# ddr32ss_EMIF_CTLCFG_0F308000h register map
Vendor: Texas Instruments
Registers are 32-bit, read-write, reset 0x0 unless marked. A register's access mark holds for its fields unless they carry their own. Offsets are as the file gives them; [hi:lo] are bit positions; {n}, {i} and the like mark numbered series.

## emif_ctlcfg (part 5 of 13)
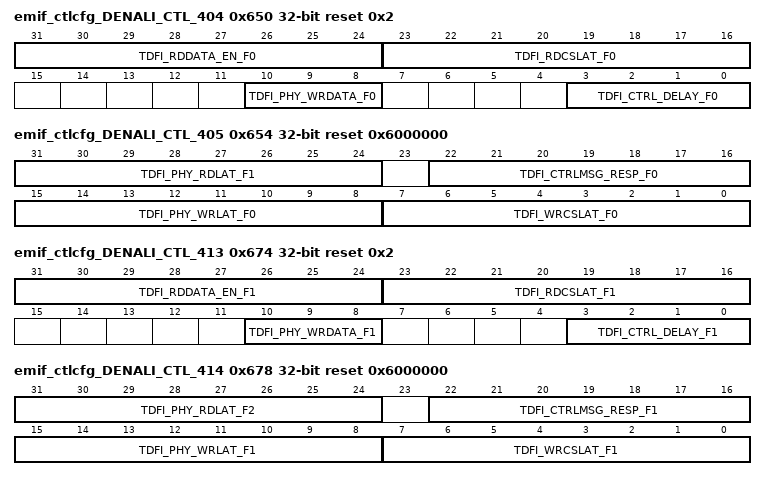
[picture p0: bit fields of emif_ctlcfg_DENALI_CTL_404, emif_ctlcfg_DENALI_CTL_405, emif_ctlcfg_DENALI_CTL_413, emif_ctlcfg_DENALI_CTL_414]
0x650 emif_ctlcfg_DENALI_CTL_404 reset 0x2
  [31:24] TDFI_RDDATA_EN_F0 — DFI tRDDATA_EN timing parameter. This is the number of DFI data phases between a read command and the first assertion of dfi_rddata_en_pN. FC=0 Reset Source: ctl_amod_g_rst_n
  [23:16] TDFI_RDCSLAT_F0 — Defines the DFI tPHY_RDCSLAT timing parameter [in DFI PHY clocks], the maximum cycles between a read command and a dfi_rddata_cs_n assertion. FC=0 Reset Source: ctl_amod_g_rst_n
  [10:8] TDFI_PHY_WRDATA_F0 — Defines the DFI tPHY_WRDATA timing parameter [in DFI PHY clocks], the maximum cycles between a dfi_wrdata_en assertion and a dfi_wrdata signal. FC=0 Reset Source: ctl_amod_g_rst_n
  [3:0] TDFI_CTRL_DELAY_F0 — Defines the DFI tCTRL_DELAY timing parameter [in DFI clocks], the delay between a DFI command change and a memory command. FC=0 Reset Source: ctl_amod_g_rst_n
0x654 emif_ctlcfg_DENALI_CTL_405 reset 0x6000000
  [31:24] TDFI_PHY_RDLAT_F1 — Defines the DFI tPHY_RDLAT timing parameter [in DFI PHY clocks], the maximum cycles between a dfi_rddata_en assertion and a dfi_rddata_valid assertion. FC=1 Reset Source: ctl_amod_g_rst_n
  [22:16] TDFI_CTRLMSG_RESP_F0 — Defines the DFI tCTRLMSG_RESP timing parameter [in DFI clocks], the maximum number of DFI clocks allowed for dfi_ctrlmsg_ack to assert after dfi_ctrlmsg_req goes high. FC=0 Reset Source: ctl_amod_g_rst_n
  [15:8] TDFI_PHY_WRLAT_F0 — DFI tPHY_WRLAT timing parameter. This is the number of DFI data phases between a write command and the first assertion of dfi_wrdata_en_pN. FC=0 Reset Source: ctl_amod_g_rst_n
  [7:0] TDFI_WRCSLAT_F0 — Defines the DFI tPHY_WRCSLAT timing parameter [in DFI PHY clocks], the maximum cycles between a write command and a dfi_wrdata_cs_n assertion. FC=0 Reset Source: ctl_amod_g_rst_n
0x658 emif_ctlcfg_DENALI_CTL_406
  [20:0] TDFI_CTRLUPD_MAX_F1 — Defines the DFI tCTRLUPD_MAX timing parameter [in DFI clocks], the maximum cycles that dfi_ctrlupd_req can be asserted. If programmed to a non-zero, a timing violation will cause an interrupt and bit [0] set in the UPDATE_ERROR_STATUS parameter. FC=1 Reset Source: ctl_amod_g_rst_n
{0x0+4i} emif_ctlcfg_DENALI_CTL_{i} (i=407..410)
  [31:0] TDFI_PHYUPD_TYPE{i-407}_F1 — Defines the DFI tPHYUPD_TYPE{i-407} timing parameter [in DFI clocks], the maximum cycles that dfi_phyupd_req can assert after dfi_phyupd_ack for dfi_phyupd_type {i-407}. If programmed to a non-zero, a timing violation will cause an interrupt and bit [{i-406}] set in the UPDATE_ERROR_STATUS parameter. FC=1 Reset Source: ctl_amod_g_rst_n
0x66C emif_ctlcfg_DENALI_CTL_411
  [22:0] TDFI_PHYUPD_RESP_F1 — Defines the DFI tPHYUPD_RESP timing parameter [in DFI clocks], the maximum cycles between a dfi_phyupd_req assertion and a dfi_phyupd_ack assertion. If programmed to a non-zero, a timing violation will cause an interrupt and bit [5] set in the UPDATE_ERROR_STATUS parameter. FC=1 Reset Source: ctl_amod_g_rst_n
0x670 emif_ctlcfg_DENALI_CTL_412
  [31:0] TDFI_CTRLUPD_INTERVAL_F1 — Defines the DFI tCTRLUPD_INTERVAL timing parameter [in DFI clocks], the maximum cycles between dfi_ctrlupd_req assertions. If programmed to a non-zero, a timing violation will cause an interrupt and bit [6] set in the UPDATE_ERROR_STATUS parameter. FC=1 Reset Source: ctl_amod_g_rst_n
0x674 emif_ctlcfg_DENALI_CTL_413 reset 0x2
  [31:24] TDFI_RDDATA_EN_F1 — DFI tRDDATA_EN timing parameter. This is the number of DFI data phases between a read command and the first assertion of dfi_rddata_en_pN. FC=1 Reset Source: ctl_amod_g_rst_n
  [23:16] TDFI_RDCSLAT_F1 — Defines the DFI tPHY_RDCSLAT timing parameter [in DFI PHY clocks], the maximum cycles between a read command and a dfi_rddata_cs_n assertion. FC=1 Reset Source: ctl_amod_g_rst_n
  [10:8] TDFI_PHY_WRDATA_F1 — Defines the DFI tPHY_WRDATA timing parameter [in DFI PHY clocks], the maximum cycles between a dfi_wrdata_en assertion and a dfi_wrdata signal. FC=1 Reset Source: ctl_amod_g_rst_n
  [3:0] TDFI_CTRL_DELAY_F1 — Defines the DFI tCTRL_DELAY timing parameter [in DFI clocks], the delay between a DFI command change and a memory command. FC=1 Reset Source: ctl_amod_g_rst_n
0x678 emif_ctlcfg_DENALI_CTL_414 reset 0x6000000
  [31:24] TDFI_PHY_RDLAT_F2 — Defines the DFI tPHY_RDLAT timing parameter [in DFI PHY clocks], the maximum cycles between a dfi_rddata_en assertion and a dfi_rddata_valid assertion. FC=2 Reset Source: ctl_amod_g_rst_n
  [22:16] TDFI_CTRLMSG_RESP_F1 — Defines the DFI tCTRLMSG_RESP timing parameter [in DFI clocks], the maximum number of DFI clocks allowed for dfi_ctrlmsg_ack to assert after dfi_ctrlmsg_req goes high. FC=1 Reset Source: ctl_amod_g_rst_n
  [15:8] TDFI_PHY_WRLAT_F1 — DFI tPHY_WRLAT timing parameter. This is the number of DFI data phases between a write command and the first assertion of dfi_wrdata_en_pN. FC=1 Reset Source: ctl_amod_g_rst_n
  [7:0] TDFI_WRCSLAT_F1 — Defines the DFI tPHY_WRCSLAT timing parameter [in DFI PHY clocks], the maximum cycles between a write command and a dfi_wrdata_cs_n assertion. FC=1 Reset Source: ctl_amod_g_rst_n
0x67C emif_ctlcfg_DENALI_CTL_415
  [20:0] TDFI_CTRLUPD_MAX_F2 — Defines the DFI tCTRLUPD_MAX timing parameter [in DFI clocks], the maximum cycles that dfi_ctrlupd_req can be asserted. If programmed to a non-zero, a timing violation will cause an interrupt and bit [0] set in the UPDATE_ERROR_STATUS parameter. FC=2 Reset Source: ctl_amod_g_rst_n
{0x0+4i} emif_ctlcfg_DENALI_CTL_{i} (i=416..419)
  [31:0] TDFI_PHYUPD_TYPE{i-416}_F2 — Defines the DFI tPHYUPD_TYPE{i-416} timing parameter [in DFI clocks], the maximum cycles that dfi_phyupd_req can assert after dfi_phyupd_ack for dfi_phyupd_type {i-416}. If programmed to a non-zero, a timing violation will cause an interrupt and bit [{i-415}] set in the UPDATE_ERROR_STATUS parameter. FC=2 Reset Source: ctl_amod_g_rst_n
0x690 emif_ctlcfg_DENALI_CTL_420
  [22:0] TDFI_PHYUPD_RESP_F2 — Defines the DFI tPHYUPD_RESP timing parameter [in DFI clocks], the maximum cycles between a dfi_phyupd_req assertion and a dfi_phyupd_ack assertion. If programmed to a non-zero, a timing violation will cause an interrupt and bit [5] set in the UPDATE_ERROR_STATUS parameter. FC=2 Reset Source: ctl_amod_g_rst_n
0x694 emif_ctlcfg_DENALI_CTL_421
  [31:0] TDFI_CTRLUPD_INTERVAL_F2 — Defines the DFI tCTRLUPD_INTERVAL timing parameter [in DFI clocks], the maximum cycles between dfi_ctrlupd_req assertions. If programmed to a non-zero, a timing violation will cause an interrupt and bit [6] set in the UPDATE_ERROR_STATUS parameter. FC=2 Reset Source: ctl_amod_g_rst_n
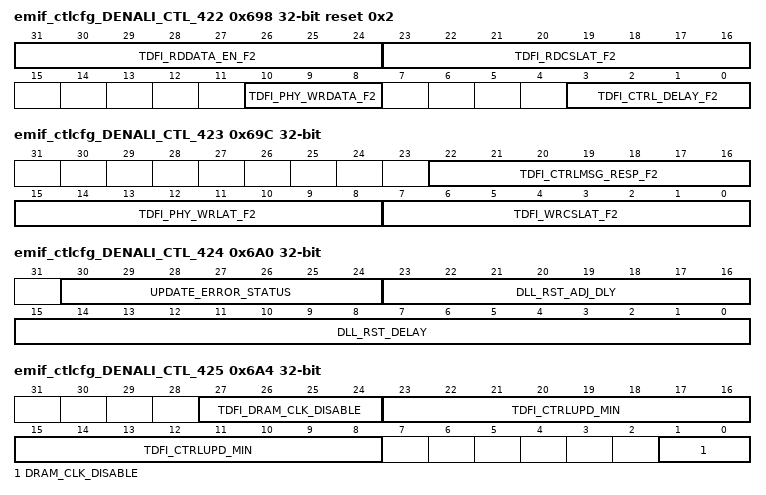
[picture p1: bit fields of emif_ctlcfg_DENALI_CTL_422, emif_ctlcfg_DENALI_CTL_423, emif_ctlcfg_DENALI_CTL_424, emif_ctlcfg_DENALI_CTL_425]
0x698 emif_ctlcfg_DENALI_CTL_422 reset 0x2
  [31:24] TDFI_RDDATA_EN_F2 — DFI tRDDATA_EN timing parameter. This is the number of DFI data phases between a read command and the first assertion of dfi_rddata_en_pN. FC=2 Reset Source: ctl_amod_g_rst_n
  [23:16] TDFI_RDCSLAT_F2 — Defines the DFI tPHY_RDCSLAT timing parameter [in DFI PHY clocks], the maximum cycles between a read command and a dfi_rddata_cs_n assertion. FC=2 Reset Source: ctl_amod_g_rst_n
  [10:8] TDFI_PHY_WRDATA_F2 — Defines the DFI tPHY_WRDATA timing parameter [in DFI PHY clocks], the maximum cycles between a dfi_wrdata_en assertion and a dfi_wrdata signal. FC=2 Reset Source: ctl_amod_g_rst_n
  [3:0] TDFI_CTRL_DELAY_F2 — Defines the DFI tCTRL_DELAY timing parameter [in DFI clocks], the delay between a DFI command change and a memory command. FC=2 Reset Source: ctl_amod_g_rst_n
0x69C emif_ctlcfg_DENALI_CTL_423
  [22:16] TDFI_CTRLMSG_RESP_F2 — Defines the DFI tCTRLMSG_RESP timing parameter [in DFI clocks], the maximum number of DFI clocks allowed for dfi_ctrlmsg_ack to assert after dfi_ctrlmsg_req goes high. FC=2 Reset Source: ctl_amod_g_rst_n
  [15:8] TDFI_PHY_WRLAT_F2 — DFI tPHY_WRLAT timing parameter. This is the number of DFI data phases between a write command and the first assertion of dfi_wrdata_en_pN. FC=2 Reset Source: ctl_amod_g_rst_n
  [7:0] TDFI_WRCSLAT_F2 — Defines the DFI tPHY_WRCSLAT timing parameter [in DFI PHY clocks], the maximum cycles between a write command and a dfi_wrdata_cs_n assertion. FC=2 Reset Source: ctl_amod_g_rst_n
0x6A0 emif_ctlcfg_DENALI_CTL_424 access per field
  [30:24] UPDATE_ERROR_STATUS ro — Identifies the source of any DFI MC-initiated or PHY-initiated update errors. Value of 1 indicates a timing violation of the associated timing parameter. READ-ONLY Reset Source: ctl_amod_g_rst_n
  [23:16] DLL_RST_ADJ_DLY rw — Minimum cycles after setting master delay in DLL until the DLL reset signal dll_rst_n may be asserted. If this signal is not being used by the PHY, this parameter may be ignored. Reset Source: ctl_amod_g_rst_n
  [15:0] DLL_RST_DELAY rw — Minimum cycles required for DLL reset signal dll_rst_n to be held. If this signal is not being used by the PHY, this parameter may be ignored. Reset Source: ctl_amod_g_rst_n
0x6A4 emif_ctlcfg_DENALI_CTL_425
  [27:24] TDFI_DRAM_CLK_DISABLE — Defines the DFI tDRAM_CLK_DISABLE timing parameter [in DFI clocks], the delay between a dfi_dram_clock_disable assertion and the memory clock disable. Reset Source: ctl_amod_g_rst_n
  [23:8] TDFI_CTRLUPD_MIN — Defines the DFI tCTRLUPD_MIN timing parameter [in DFI clocks], the minimum cycles that dfi_ctrlupd_req must be asserted. Reset Source: ctl_amod_g_rst_n
  [1:0] DRAM_CLK_DISABLE — Set value for the dfi_dram_clk_disable signal. Bit [0] controls cs0, bit [1] controls cs1, etc. Set each bit to 1 to disable. Reset Source: ctl_amod_g_rst_n
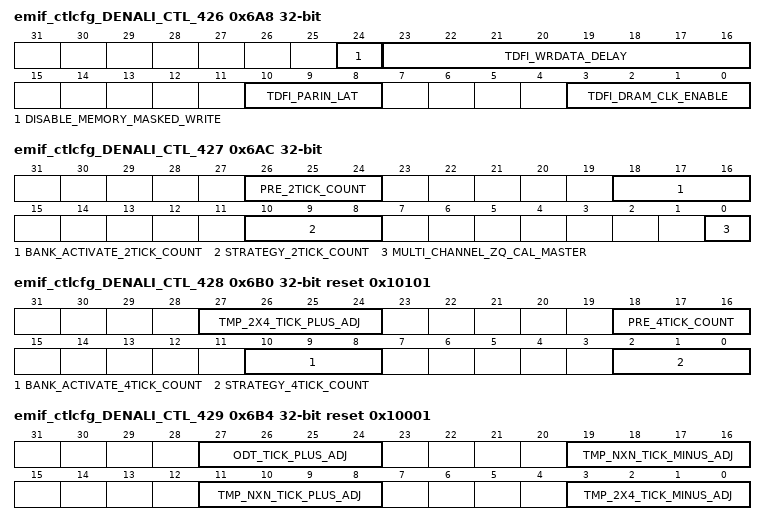
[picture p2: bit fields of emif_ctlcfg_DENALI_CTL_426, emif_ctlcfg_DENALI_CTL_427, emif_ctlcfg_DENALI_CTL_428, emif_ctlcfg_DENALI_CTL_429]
0x6A8 emif_ctlcfg_DENALI_CTL_426
  [24] DISABLE_MEMORY_MASKED_WRITE — Restricts the controller from masked write commands. Set to 1 to not issue these commands. Only used if connected to an LPDDR4 device. Reset Source: ctl_amod_g_rst_n
  [23:16] TDFI_WRDATA_DELAY — Defines the tWRDATA_DELAY timing parameter [in DFI PHY clocks], the maximum cycles between when the dfi_wrdata_en signal is asserted and when the corresponding write data transfer is completed on the DRAM bus. Reset Source: ctl_amod_g_rst_n
  [10:8] TDFI_PARIN_LAT — Defines the DFI tPARIN_LAT timing parameter [in DFI PHY clocks], the maximum cycles between a DFI command and a dfi_parity_in signal assertion. Reset Source: ctl_amod_g_rst_n
  [3:0] TDFI_DRAM_CLK_ENABLE — Defines the DFI tDRAM_CLK_ENABLE timing parameter [in DFI clocks], the delay between a dfi_dram_clk_disable de-assertion and the memory clock enable. Reset Source: ctl_amod_g_rst_n
0x6AC emif_ctlcfg_DENALI_CTL_427
  [26:24] PRE_2TICK_COUNT — NEED TO FiLL IN . Reset Source: ctl_amod_g_rst_n
  [18:16] BANK_ACTIVATE_2TICK_COUNT — NEED TO FiLL IN . Reset Source: ctl_amod_g_rst_n
  [10:8] STRATEGY_2TICK_COUNT — NEED TO FiLL IN . Reset Source: ctl_amod_g_rst_n
  [0] MULTI_CHANNEL_ZQ_CAL_MASTER — In a two controller scenario, defines if this controller will issue ZQ calibration start commands when neither controller is in a low power mode. Set to 1 to define this controller as the master that issues ZQ calibration start commands or clear to 0 to define this controller as the target. This parameter should only be programmed once during initialization. Reset Source: ctl_amod_g_rst_n
0x6B0 emif_ctlcfg_DENALI_CTL_428 reset 0x10101
  [27:24] TMP_2X4_TICK_PLUS_ADJ — NEED TO FiLL IN . Reset Source: ctl_amod_g_rst_n
  [18:16] PRE_4TICK_COUNT — NEED TO FiLL IN . Reset Source: ctl_amod_g_rst_n
  [10:8] BANK_ACTIVATE_4TICK_COUNT — NEED TO FiLL IN . Reset Source: ctl_amod_g_rst_n
  [2:0] STRATEGY_4TICK_COUNT — NEED TO FiLL IN . Reset Source: ctl_amod_g_rst_n
0x6B4 emif_ctlcfg_DENALI_CTL_429 reset 0x10001
  [27:24] ODT_TICK_PLUS_ADJ — NEED TO FiLL IN . Reset Source: ctl_amod_g_rst_n
  [19:16] TMP_NXN_TICK_MINUS_ADJ — NEED TO FiLL IN . Reset Source: ctl_amod_g_rst_n
  [11:8] TMP_NXN_TICK_PLUS_ADJ — NEED TO FiLL IN . Reset Source: ctl_amod_g_rst_n
  [3:0] TMP_2X4_TICK_MINUS_ADJ — NEED TO FiLL IN . Reset Source: ctl_amod_g_rst_n
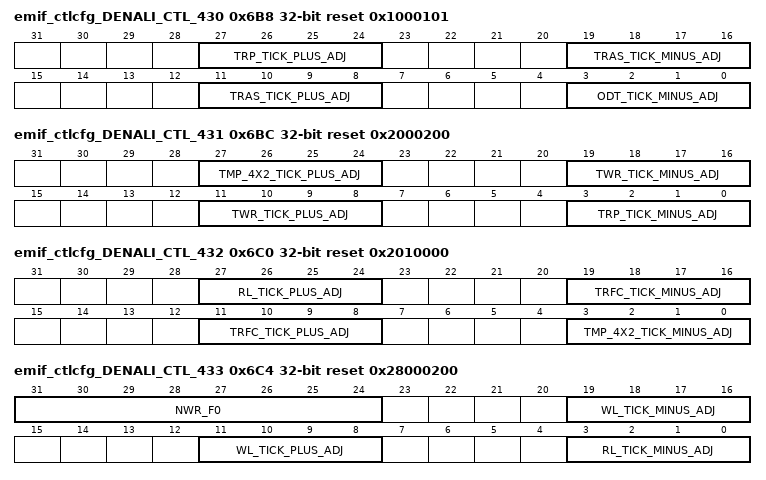
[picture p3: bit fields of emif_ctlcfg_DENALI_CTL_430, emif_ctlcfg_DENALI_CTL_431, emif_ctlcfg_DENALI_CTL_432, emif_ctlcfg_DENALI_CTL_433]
0x6B8 emif_ctlcfg_DENALI_CTL_430 reset 0x1000101
  [27:24] TRP_TICK_PLUS_ADJ — NEED TO FiLL IN . Reset Source: ctl_amod_g_rst_n
  [19:16] TRAS_TICK_MINUS_ADJ — NEED TO FiLL IN . Reset Source: ctl_amod_g_rst_n
  [11:8] TRAS_TICK_PLUS_ADJ — NEED TO FiLL IN . Reset Source: ctl_amod_g_rst_n
  [3:0] ODT_TICK_MINUS_ADJ — NEED TO FiLL IN . Reset Source: ctl_amod_g_rst_n
0x6BC emif_ctlcfg_DENALI_CTL_431 reset 0x2000200
  [27:24] TMP_4X2_TICK_PLUS_ADJ — NEED TO FiLL IN . Reset Source: ctl_amod_g_rst_n
  [19:16] TWR_TICK_MINUS_ADJ — NEED TO FiLL IN . Reset Source: ctl_amod_g_rst_n
  [11:8] TWR_TICK_PLUS_ADJ — NEED TO FiLL IN . Reset Source: ctl_amod_g_rst_n
  [3:0] TRP_TICK_MINUS_ADJ — NEED TO FiLL IN . Reset Source: ctl_amod_g_rst_n
0x6C0 emif_ctlcfg_DENALI_CTL_432 reset 0x2010000
  [27:24] RL_TICK_PLUS_ADJ — NEED TO FiLL IN . Reset Source: ctl_amod_g_rst_n
  [19:16] TRFC_TICK_MINUS_ADJ — NEED TO FiLL IN . Reset Source: ctl_amod_g_rst_n
  [11:8] TRFC_TICK_PLUS_ADJ — NEED TO FiLL IN . Reset Source: ctl_amod_g_rst_n
  [3:0] TMP_4X2_TICK_MINUS_ADJ — NEED TO FiLL IN . Reset Source: ctl_amod_g_rst_n
0x6C4 emif_ctlcfg_DENALI_CTL_433 reset 0x28000200
  [31:24] NWR_F0 — DRAM NWR value in cycles. FC=0 Reset Source: ctl_amod_g_rst_n
  [19:16] WL_TICK_MINUS_ADJ — NEED TO FiLL IN . Reset Source: ctl_amod_g_rst_n
  [11:8] WL_TICK_PLUS_ADJ — NEED TO FiLL IN . Reset Source: ctl_amod_g_rst_n
  [3:0] RL_TICK_MINUS_ADJ — NEED TO FiLL IN . Reset Source: ctl_amod_g_rst_n
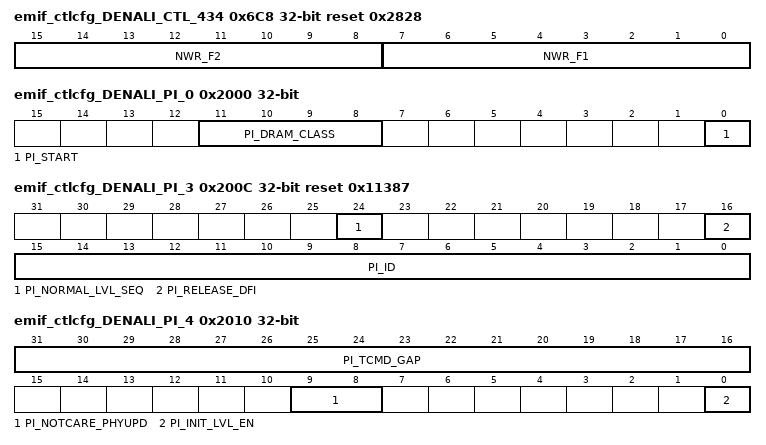
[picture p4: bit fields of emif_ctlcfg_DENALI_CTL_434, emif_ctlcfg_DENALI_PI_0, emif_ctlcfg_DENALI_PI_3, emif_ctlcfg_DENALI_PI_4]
0x6C8 emif_ctlcfg_DENALI_CTL_434 reset 0x2828
  [15:8] NWR_F2 — DRAM NWR value in cycles. FC=2 Reset Source: ctl_amod_g_rst_n
  [7:0] NWR_F1 — DRAM NWR value in cycles. FC=1 Reset Source: ctl_amod_g_rst_n
0x2000 emif_ctlcfg_DENALI_PI_0
  [11:8] PI_DRAM_CLASS — Defines the memory class for the PI. Reset Source: ctl_amod_g_rst_n
  [0] PI_START — Initiate command processing in the PI. Set to 1 to initiate. Reset Source: ctl_amod_g_rst_n
0x2004 emif_ctlcfg_DENALI_PI_1 ro reset 0x30BD08BA
  [31:0] PI_VERSION_0 — Holds the PI version number. This is a unique number for each PHY IP delivery. This will help in identifying different version of the PHY IP. READ-ONLY Reset Source: ctl_amod_g_rst_n
0x2008 emif_ctlcfg_DENALI_PI_2 ro reset 0x453CB5C
  [31:0] PI_VERSION_1 — Holds the PI version number. This is a unique number for each PHY IP delivery. This will help in identifying different version of the PHY IP. READ-ONLY Reset Source: ctl_amod_g_rst_n
0x200C emif_ctlcfg_DENALI_PI_3 access per field reset 0x11387
  [24] PI_NORMAL_LVL_SEQ rw — Enable the PI to finish all the pending leveling before releasing the DFI bus. Reset Source: ctl_amod_g_rst_n
  [16] PI_RELEASE_DFI ro — This is a status whether PI has release DFI. READ-ONLY. Reset Source: ctl_amod_g_rst_n
  [15:0] PI_ID ro — Holds the PI ID number. This is a Cadence DDR PHY IP identifier. It is set to 0x1387. READ-ONLY Reset Source: ctl_amod_g_rst_n
0x2010 emif_ctlcfg_DENALI_PI_4
  [31:16] PI_TCMD_GAP — Specifies the minimum gap in DFI clocks between two commands. Used to guard the timing from the last command of MC and the first command of PI when MC hand over the control of DFI to PI. Reset Source: ctl_amod_g_rst_n
  [9:8] PI_NOTCARE_PHYUPD — Allow the PI to issue a master request to the controller if a phyupd_req from the PHY has been detected.bit[1] represents supports in normal state;bit[0] represents supports in initialization state. Set to 1 to issue the master request. Reset Source: ctl_amod_g_rst_n
  [0] PI_INIT_LVL_EN — Enables the initial leveling sequence after PI initialization procedure. Set to 1 to enable. Reset Source: ctl_amod_g_rst_n
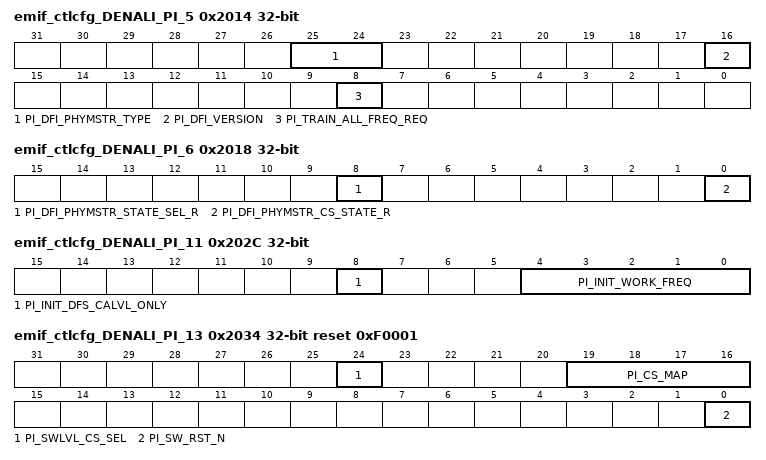
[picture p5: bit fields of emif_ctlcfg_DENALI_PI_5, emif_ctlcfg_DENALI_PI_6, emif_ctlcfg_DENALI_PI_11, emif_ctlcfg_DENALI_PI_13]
0x2014 emif_ctlcfg_DENALI_PI_5 access per field
  [25:24] PI_DFI_PHYMSTR_TYPE rw — DFI Master Request Type used for dfi 4.1 verision: This signal indicates the required state of DRAM when PHY becomes the master. Each memory rank uses one bit. 1'b0: IDLE. The MC should close all the pages. 1'b1: IDLE or Self Refresh. Reset Source: ctl_amod_g_rst_n
  [16] PI_DFI_VERSION rw — Define the DFI master version, set 1 for DFI4.1, set 0 for DFI4.0 Reset Source: ctl_amod_g_rst_n
  [8] PI_TRAIN_ALL_FREQ_REQ wo — Triggers training for all supported frequencies in PI_FREQ_MAP. Applies to LPDDR4 devices onlyh. Set to 1 to trigger. Only applicable after memory initialization has been completed. Can be used to train new frequencies that were not available at initialization time. WRITE-ONLY Reset Source: ctl_amod_g_rst_n
0x2018 emif_ctlcfg_DENALI_PI_6
  [8] PI_DFI_PHYMSTR_STATE_SEL_R — DFI PHY Master State Select: Indication from the PHY to the MC whether the requested memory state is IDLE or Self refresh. 'b0: indicates that the corresponding CS must be put into the IDLE state. 'b1: indicates that the corresponding CS must be put into the Self refresh state. Reset Source: ctl_amod_g_rst_n
  [0] PI_DFI_PHYMSTR_CS_STATE_R — This signal indicates the state of the DRAM when the PHY becomes the master. 'b0: The PHY specifies the required state, using the dfi_phymstr_state_sel signal. 'b1: is reserved. Reset Source: ctl_amod_g_rst_n
0x201C emif_ctlcfg_DENALI_PI_7 ro
  [31:0] PI_TDFI_PHYMSTR_MAX — Indicates the maximum number of DFI clock cycles registered while the dfi_phymstr_req signal is asserted and the dfi_phymstr_ack signal is asserted. READ-ONLY. Reset Source: ctl_amod_g_rst_n
0x2020 emif_ctlcfg_DENALI_PI_8 ro
  [19:0] PI_TDFI_PHYMSTR_RESP — Indicates the maximum number of DFI clock cycles registered between a dfi_phymstr_req signal assertion and a dfi_phymstr_ack signal assertion. READ-ONLY Reset Source: ctl_amod_g_rst_n
0x2024 emif_ctlcfg_DENALI_PI_9 ro
  [19:0] PI_TDFI_PHYUPD_RESP — Indicates the maximum number of DFI clock cycles registered between a dfi_phyupd_req signal assertion and a dfi_phyupd_ack signal assertion. READ-ONLY. Reset Source: ctl_amod_g_rst_n
0x2028 emif_ctlcfg_DENALI_PI_10 ro
  [31:0] PI_TDFI_PHYUPD_MAX — Indicates the maximum number of DFI clock cycles registered while the dfi_phyupd_req signal is asserted and the dfi_phy_ack signal is asserted. READ-ONLY. Reset Source: ctl_amod_g_rst_n
0x202C emif_ctlcfg_DENALI_PI_11
  [8] PI_INIT_DFS_CALVL_ONLY — Enables frequency training for CA leveling only. Other trainings are not performed. Reset Source: ctl_amod_g_rst_n
  [4:0] PI_INIT_WORK_FREQ — Indicates the initial work frequency after initialization and initial leveling sequence. Reset Source: ctl_amod_g_rst_n
0x2030 emif_ctlcfg_DENALI_PI_12
  [31:0] PI_FREQ_MAP — Frequency map for supported working frequencies. Each bit represents one supported frequency. Reset Source: ctl_amod_g_rst_n
0x2034 emif_ctlcfg_DENALI_PI_13 reset 0xF0001
  [24] PI_SWLVL_CS_SEL — Defines which chip selects are active in swlvl, 0 for binary, 1 for one-hot. Reset Source: ctl_amod_g_rst_n
  [19:16] PI_CS_MAP — Defines which chip selects are active. Reset Source: ctl_amod_g_rst_n
  [0] PI_SW_RST_N — User request to reset the whole PI except the parameter modules. Set 0 to reset, set to 1 to release. Reset Source: ctl_amod_g_rst_n
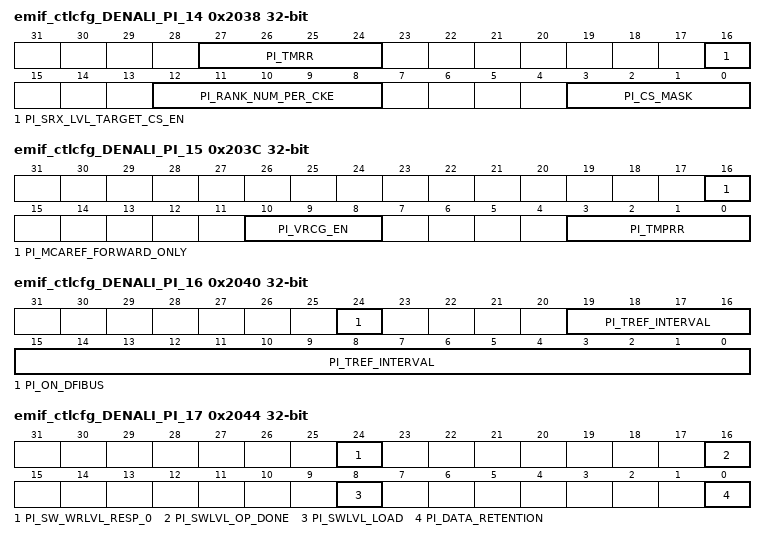
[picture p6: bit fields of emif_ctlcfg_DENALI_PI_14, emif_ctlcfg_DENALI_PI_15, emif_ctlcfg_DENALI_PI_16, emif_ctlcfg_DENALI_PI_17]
0x2038 emif_ctlcfg_DENALI_PI_14
  [27:24] PI_TMRR — DRAM tMRR value in memory clock cycles. Reset Source: ctl_amod_g_rst_n
  [16] PI_SRX_LVL_TARGET_CS_EN — Defines self refresh exit trigger target rank/ranks training or all ranks training. 1: The rank/ranks exit from self refresh will trigger the corresponding rank/ranks training. Note: If multiple ranks exit from self refresh, current design only support the multiple ranks srx command issues at the same time. 0: Any rank/ranks exit from self refresh will trigger all ranks training Reset Source: ctl_amod_g_rst_n
  [12:8] PI_RANK_NUM_PER_CKE — Defines the number of chip selects share one cke Reset Source: ctl_amod_g_rst_n
  [3:0] PI_CS_MASK — Defines which chip selects are active. Reset Source: ctl_amod_g_rst_n
0x203C emif_ctlcfg_DENALI_PI_15
  [16] PI_MCAREF_FORWARD_ONLY — Controls the generation of AREF from the PI module or forward the MC received value. Reset Source: ctl_amod_g_rst_n
  [10:8] PI_VRCG_EN — Whether enable VRCG mode in two cases: bit0 - when DFS. bit1-when setting DQ Vref. bit2-when setting CBT. Reset Source: ctl_amod_g_rst_n
  [3:0] PI_TMPRR — DRAM tMPRR value in memory clock cycles. Reset Source: ctl_amod_g_rst_n
0x2040 emif_ctlcfg_DENALI_PI_16 access per field
  [24] PI_ON_DFIBUS ro — Monitors the state of the PI controlling the DFI bus. 1 means PI is in control. READ-ONLY. Reset Source: ctl_amod_g_rst_n
  [19:0] PI_TREF_INTERVAL rw — Defines the cycles between refreshes to different chip selects. Reset Source: ctl_amod_g_rst_n
0x2044 emif_ctlcfg_DENALI_PI_17 access per field
  [24] PI_SW_WRLVL_RESP_0 ro — Write leveling response for data slice 0. READ-ONLY Reset Source: ctl_amod_g_rst_n
  [16] PI_SWLVL_OP_DONE ro — Reports the status of the software leveling operation. Value of 1 indicates operation complete. READ-ONLY Reset Source: ctl_amod_g_rst_n
  [8] PI_SWLVL_LOAD wo — User request to load delays and execute software leveling. Set to 1 to trigger. WRITE-ONLY Reset Source: ctl_amod_g_rst_n
  [0] PI_DATA_RETENTION ro — Monitors the readiness for the PHY to be put into data retention mode after pi_sref_entry req parameter has been written. 1 means ready for data retention. READ-ONLY. Reset Source: ctl_amod_g_rst_n
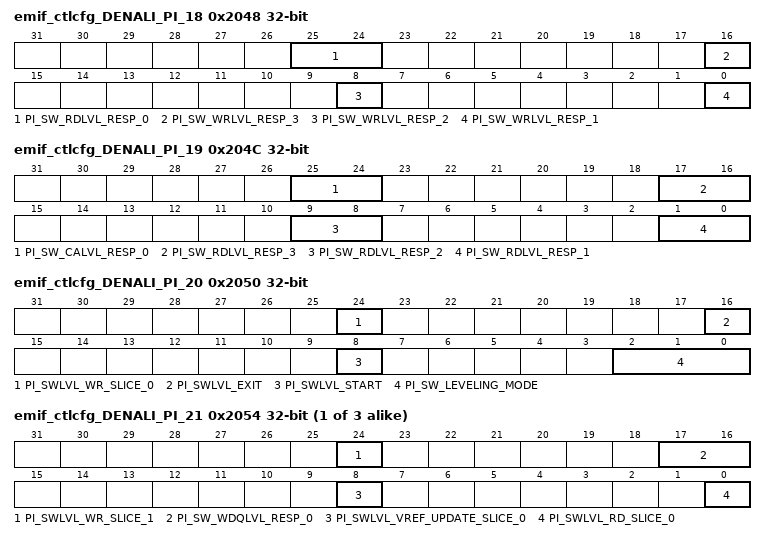
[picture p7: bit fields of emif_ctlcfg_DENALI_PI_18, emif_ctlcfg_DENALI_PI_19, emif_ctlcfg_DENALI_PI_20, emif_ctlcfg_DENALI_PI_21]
0x2048 emif_ctlcfg_DENALI_PI_18 ro
  [25:24] PI_SW_RDLVL_RESP_0 — Read leveling response for data slice 0. READ-ONLY Reset Source: ctl_amod_g_rst_n
  [16] PI_SW_WRLVL_RESP_3 — Write leveling response for data slice 3. READ-ONLY Reset Source: ctl_amod_g_rst_n
  [8] PI_SW_WRLVL_RESP_2 — Write leveling response for data slice 2. READ-ONLY Reset Source: ctl_amod_g_rst_n
  [0] PI_SW_WRLVL_RESP_1 — Write leveling response for data slice 1. READ-ONLY Reset Source: ctl_amod_g_rst_n
0x204C emif_ctlcfg_DENALI_PI_19 ro
  [25:24] PI_SW_CALVL_RESP_0 — CA leveling response for address slice 0. READ-ONLY Reset Source: ctl_amod_g_rst_n
  [17:16] PI_SW_RDLVL_RESP_3 — Read leveling response for data slice 3. READ-ONLY Reset Source: ctl_amod_g_rst_n
  [9:8] PI_SW_RDLVL_RESP_2 — Read leveling response for data slice 2. READ-ONLY Reset Source: ctl_amod_g_rst_n
  [1:0] PI_SW_RDLVL_RESP_1 — Read leveling response for data slice 1. READ-ONLY Reset Source: ctl_amod_g_rst_n
0x2050 emif_ctlcfg_DENALI_PI_20 access per field
  [24] PI_SWLVL_WR_SLICE_0 wo — SW leveling write command in WDQ training. WRITE-ONLY Reset Source: ctl_amod_g_rst_n
  [16] PI_SWLVL_EXIT wo — User request to exit software leveling. Set to 1 to exit. WRITE-ONLY Reset Source: ctl_amod_g_rst_n
  [8] PI_SWLVL_START wo — User request to initiate software leveling of type in the SW_LEVELING_MODE parameter. Set to 1 to trigger. WRITE-ONLY Reset Source: ctl_amod_g_rst_n
  [2:0] PI_SW_LEVELING_MODE rw — Defines the leveling operation for software leveling. Set to 'b111 for DDR4 VREF training, set to b001 for write leveling, set to b010 for read data eye training, or set to b011 for read gate training, set to b100 for ca training, set to b101 for wdq training. Reset Source: ctl_amod_g_rst_n
{0x2000+4i} emif_ctlcfg_DENALI_PI_{i} access per field (i=21..23)
  [24] PI_SWLVL_WR_SLICE_{i-20} wo — SW leveling write command in WDQ training. WRITE-ONLY Reset Source: ctl_amod_g_rst_n
  [17:16] PI_SW_WDQLVL_RESP_{i-21} ro — Leveling response for data slice {i-21}. READ-ONLY Reset Source: ctl_amod_g_rst_n
  [8] PI_SWLVL_VREF_UPDATE_SLICE_{i-21} wo — SW leveling vref update command in WDQ training. WRITE-ONLY Reset Source: ctl_amod_g_rst_n
  [0] PI_SWLVL_RD_SLICE_{i-21} wo — SW leveling read command in WDQ training. WRITE-ONLY Reset Source: ctl_amod_g_rst_n
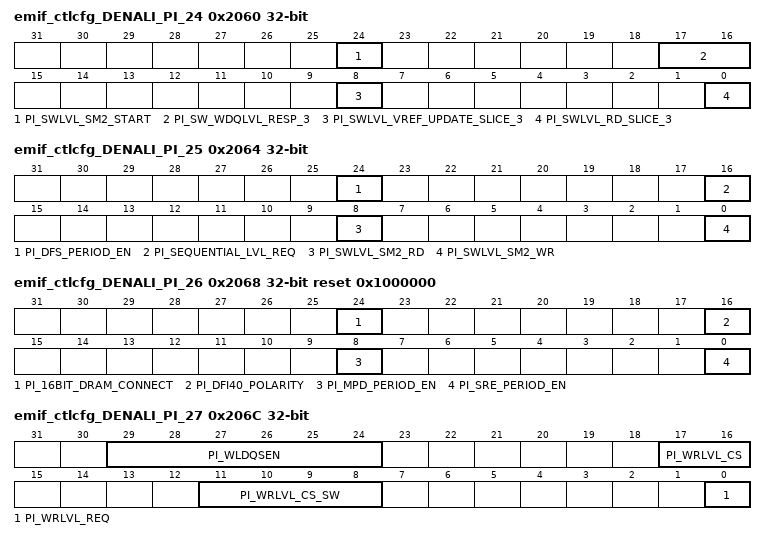
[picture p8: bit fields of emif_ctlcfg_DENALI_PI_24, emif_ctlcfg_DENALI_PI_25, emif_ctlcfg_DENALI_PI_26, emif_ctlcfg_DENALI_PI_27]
0x2060 emif_ctlcfg_DENALI_PI_24 access per field
  [24] PI_SWLVL_SM2_START wo — SW leveling start command for stage 2. WRITE-ONLY Reset Source: ctl_amod_g_rst_n
  [17:16] PI_SW_WDQLVL_RESP_3 ro — Leveling response for data slice 3. READ-ONLY Reset Source: ctl_amod_g_rst_n
  [8] PI_SWLVL_VREF_UPDATE_SLICE_3 wo — SW leveling vref update command in WDQ training. WRITE-ONLY Reset Source: ctl_amod_g_rst_n
  [0] PI_SWLVL_RD_SLICE_3 wo — SW leveling read command in WDQ training. WRITE-ONLY Reset Source: ctl_amod_g_rst_n
0x2064 emif_ctlcfg_DENALI_PI_25 access per field
  [24] PI_DFS_PERIOD_EN rw — Enable the DFS triggered periodic leveling. Reset Source: ctl_amod_g_rst_n
  [16] PI_SEQUENTIAL_LVL_REQ wo — User request to initiate all possible leveling sequences. Set to 1 to trigger. WRITE-ONLY Reset Source: ctl_amod_g_rst_n
  [8] PI_SWLVL_SM2_RD wo — SW leveling read command for stage 2. WRITE-ONLY Reset Source: ctl_amod_g_rst_n
  [0] PI_SWLVL_SM2_WR wo — SW leveling write command for stage 2. WRITE-ONLY Reset Source: ctl_amod_g_rst_n
0x2068 emif_ctlcfg_DENALI_PI_26 reset 0x1000000
  [24] PI_16BIT_DRAM_CONNECT — Enable 16/32 bit DRAM configuration. 0: 16bit DRAM. 1: 32 bit DRAM. Reset Source: ctl_amod_g_rst_n
  [16] PI_DFI40_POLARITY — Defines the polarity of the dfi_wrdata_cs_n/dfi_rddata_cs_n signals. Reset Source: ctl_amod_g_rst_n
  [8] PI_MPD_PERIOD_EN — Enable the max power saving mode exit triggered periodic leveling. Reset Source: ctl_amod_g_rst_n
  [0] PI_SRE_PERIOD_EN — Enable the self refresh exit triggered periodic leveling. Reset Source: ctl_amod_g_rst_n
0x206C emif_ctlcfg_DENALI_PI_27 access per field
  [29:24] PI_WLDQSEN rw — Delay from issuing MRS to first DQS strobe for write leveling. Reset Source: ctl_amod_g_rst_n
  [17:16] PI_WRLVL_CS rw — Specifies the target chip select for the write leveling operation initiated through the WRLVL_REQ parameter. Reset Source: ctl_amod_g_rst_n
  [11:8] PI_WRLVL_CS_SW rw — Specifies the target chip select for the write leveling operation initiated through the WRLVL_REQ parameter. Reset Source: ctl_amod_g_rst_n
  [0] PI_WRLVL_REQ wo — User request to initiate write leveling. Set to 1 to trigger. WRITE-ONLY Reset Source: ctl_amod_g_rst_n
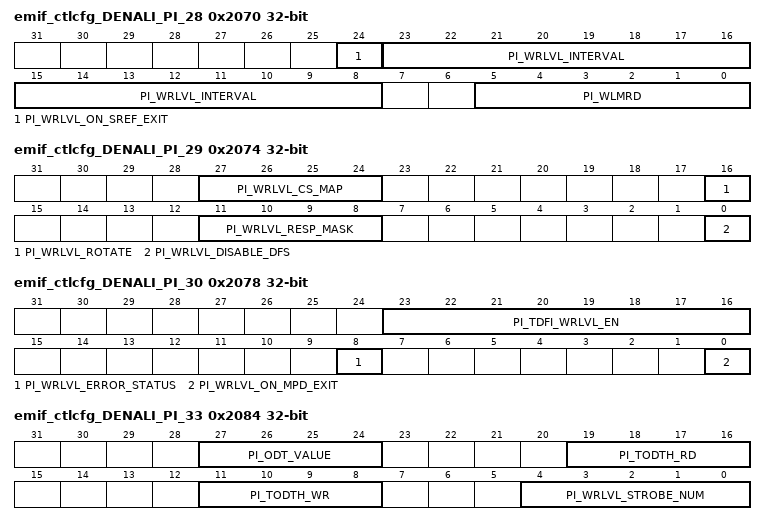
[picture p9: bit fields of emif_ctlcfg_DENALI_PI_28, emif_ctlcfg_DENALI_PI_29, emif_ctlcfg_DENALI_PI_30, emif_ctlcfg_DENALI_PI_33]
0x2070 emif_ctlcfg_DENALI_PI_28
  [24] PI_WRLVL_ON_SREF_EXIT — Enables automatic write leveling on a self-refresh exit. Set to 1 to enable. Reset Source: ctl_amod_g_rst_n
  [23:8] PI_WRLVL_INTERVAL — Number of long count sequences counted between automatic write leveling commands. Reset Source: ctl_amod_g_rst_n
  [5:0] PI_WLMRD — Delay from issuing MRS to first write leveling strobe. Reset Source: ctl_amod_g_rst_n
0x2074 emif_ctlcfg_DENALI_PI_29
  [27:24] PI_WRLVL_CS_MAP — Defines the chip select map for write leveling operations. Bit [0] controls cs0, bit [1] controls cs1, etc. Set each bit to 1 to enable chip for write leveling. Reset Source: ctl_amod_g_rst_n
  [16] PI_WRLVL_ROTATE — Enables rotational CS for counter triggered automatic write leveling. Set to 1, only one rank's write levling will process, the rank number is rotational for each time that write leveling been triggered by counter expiring. Set to 0 or not a short pattern leveling [indicated by dfi_lvl_periodic], the counter expired write leveling will process all the ranks. Reset Source: ctl_amod_g_rst_n
  [11:8] PI_WRLVL_RESP_MASK — Mask for the dfi_wrlvl_resp signal during write leveling. Reset Source: ctl_amod_g_rst_n
  [0] PI_WRLVL_DISABLE_DFS — Disable automatic write leveling on freq change. Set to 1 to disable wrlvl on dfs,set 0 enable wrlvl on dfs. Reset Source: ctl_amod_g_rst_n
0x2078 emif_ctlcfg_DENALI_PI_30 access per field
  [23:16] PI_TDFI_WRLVL_EN rw — Defines the DFI tWRLVL_EN timing parameter [in DFI clocks], the minimum cycles from a dfi_wrlvl_en assertion to the first dfi_wrlvl_strobe assertion. Reset Source: ctl_amod_g_rst_n
  [8] PI_WRLVL_ERROR_STATUS ro — Holds the error associated with the write level error interrupt. Bit [0] set indicates a TDFI_WRLVL_MAX parameter violation and bit [1] set indicates a TDFI_WRLVL_RESP parameter violation. READ-ONLY Reset Source: ctl_amod_g_rst_n
  [0] PI_WRLVL_ON_MPD_EXIT rw — Enables automatic write leveling on a maximum power down mode exit. Set to 1 to enable. Reset Source: ctl_amod_g_rst_n
0x207C emif_ctlcfg_DENALI_PI_31
  [31:0] PI_TDFI_WRLVL_RESP — Defines the DFI tWRLVL_RESP timing parameter [in DFI clocks], the maximum cycles between a dfi_wrlvl_req assertion and a dfi_wrlvl_en assertion. Reset Source: ctl_amod_g_rst_n
0x2080 emif_ctlcfg_DENALI_PI_32
  [31:0] PI_TDFI_WRLVL_MAX — Defines the DFI tWRLVL_MAX timing parameter [in DFI clocks], the maximum cycles between a dfi_wrlvl_en assertion and a valid dfi_wrlvl_resp. Reset Source: ctl_amod_g_rst_n
0x2084 emif_ctlcfg_DENALI_PI_33
  [27:24] PI_ODT_VALUE — When using LPDDR4, this value will be driven out on the dfi_odt signal. Reset Source: ctl_amod_g_rst_n
  [19:16] PI_TODTH_RD — Defines the minimum DRAM cycles of ODT high time for a read command, in memory clocks. Reset Source: ctl_amod_g_rst_n
  [11:8] PI_TODTH_WR — Defines the minimum DRAM cycles of ODT high time for a write command, in memory clocks. Reset Source: ctl_amod_g_rst_n
  [4:0] PI_WRLVL_STROBE_NUM — Defines the number of write leveling strobes generated. Reset Source: ctl_amod_g_rst_n
0x2088 emif_ctlcfg_DENALI_PI_34
  [3:0] PI_ADDRESS_MIRRORING — Indicates which chip selects support address mirroring. Bit [0] controls cs0, bit [1] controls cs1, etc. Set each bit to 1 to enable. Reset Source: ctl_amod_g_rst_n
0x208C emif_ctlcfg_DENALI_PI_35
  [25:0] PI_CA_PARITY_ERROR_INJECT — Selects bit to corrupt on the CA bus for CA parity error injection. Reset Source: ctl_amod_g_rst_n
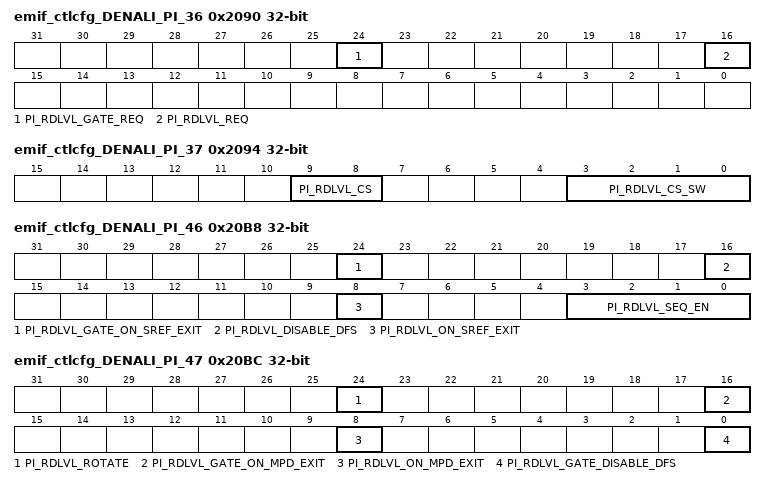
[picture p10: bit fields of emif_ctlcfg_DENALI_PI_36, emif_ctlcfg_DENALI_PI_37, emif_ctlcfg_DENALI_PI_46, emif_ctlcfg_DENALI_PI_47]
0x2090 emif_ctlcfg_DENALI_PI_36 wo
  [24] PI_RDLVL_GATE_REQ — User request to initiate gate training. Set to 1 to trigger. WRITE-ONLY Reset Source: ctl_amod_g_rst_n
  [16] PI_RDLVL_REQ — User request to initiate data eye training. Set to 1 to trigger. WRITE-ONLY Reset Source: ctl_amod_g_rst_n
0x2094 emif_ctlcfg_DENALI_PI_37
  [9:8] PI_RDLVL_CS — Specifies the target chip select for the data eye training operation initiated through the RDLVL_REQ parameter or the gate training operation initiated through the RDLVL_GATE_REQ parameter. Reset Source: ctl_amod_g_rst_n
  [3:0] PI_RDLVL_CS_SW — Specifies the target chip select for the data eye training operation initiated through the RDLVL_REQ parameter or the gate training operation initiated through the RDLVL_GATE_REQ parameter. Reset Source: ctl_amod_g_rst_n
{0x2000+4i} emif_ctlcfg_DENALI_PI_{i} (i=38..45)
  [31:0] PI_RDLVL_PAT_{i-38} — Non-default pattern {i-38} used for read data eye training of DDR4 or LPDDR4, and read dbi training of DDR4. Reset Source: ctl_amod_g_rst_n
0x20B8 emif_ctlcfg_DENALI_PI_46
  [24] PI_RDLVL_GATE_ON_SREF_EXIT — Enables automatic gate training on a self-refresh exit. Set to 1 to enable. Reset Source: ctl_amod_g_rst_n
  [16] PI_RDLVL_DISABLE_DFS — Disables automatic data eye training on freq change. Set to 1 to disable rdlvl on dfs,Set to 0 to enable rdlvl on dfs. Reset Source: ctl_amod_g_rst_n
  [8] PI_RDLVL_ON_SREF_EXIT — Enables automatic data eye training on a self-refresh exit. Set to 1 to enable. Reset Source: ctl_amod_g_rst_n
  [3:0] PI_RDLVL_SEQ_EN — Specifies the pattern, format and MPR for data eye training. Reset Source: ctl_amod_g_rst_n
0x20BC emif_ctlcfg_DENALI_PI_47
  [24] PI_RDLVL_ROTATE — Enables rotational CS for interval data eye training. Set to 1 for rotating CS. Reset Source: ctl_amod_g_rst_n
  [16] PI_RDLVL_GATE_ON_MPD_EXIT — Enables automatic gate training on a maximum power down mode exit. Set to 1 to enable. Reset Source: ctl_amod_g_rst_n
  [8] PI_RDLVL_ON_MPD_EXIT — Enables automatic data eye training on a maximum power down mode exit. Set to 1 to enable. Reset Source: ctl_amod_g_rst_n
  [0] PI_RDLVL_GATE_DISABLE_DFS — Disables automatic gate training on freq change. Set to 1 to disable rdlvl_gate on dfs,Set to 0 to enable rdlvl_gate on dfs. Reset Source: ctl_amod_g_rst_n
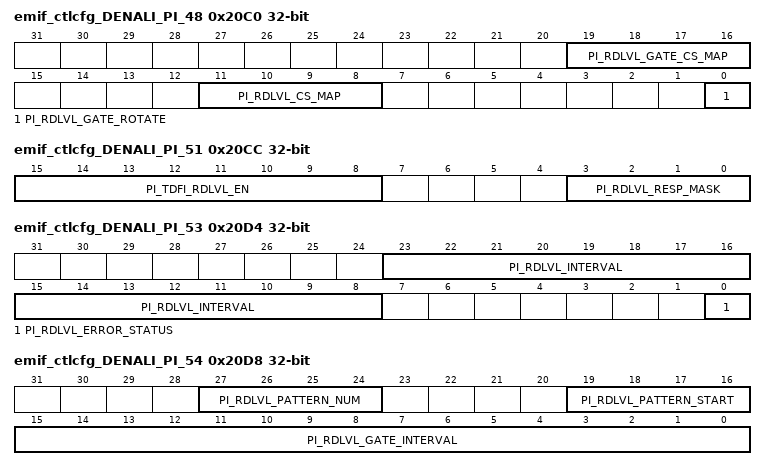
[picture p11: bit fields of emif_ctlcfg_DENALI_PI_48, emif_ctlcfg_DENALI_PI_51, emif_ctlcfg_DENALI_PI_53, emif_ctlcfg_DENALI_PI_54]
0x20C0 emif_ctlcfg_DENALI_PI_48
  [19:16] PI_RDLVL_GATE_CS_MAP — Defines the chip select map for gate training operations. Bit [0] controls cs0, bit [1] controls cs1, etc. Set each bit to 1 to enable chip for gate training. Reset Source: ctl_amod_g_rst_n
  [11:8] PI_RDLVL_CS_MAP — Defines the chip select map for data eye training operations. Bit [0] controls cs0, bit [1] controls cs1, etc. Set each bit to 1 to enable chip for data eye training. Reset Source: ctl_amod_g_rst_n
  [0] PI_RDLVL_GATE_ROTATE — Enables rotational CS for interval gate training. Set to 1 for rotating CS. Reset Source: ctl_amod_g_rst_n
0x20C4 emif_ctlcfg_DENALI_PI_49
  [9:0] PI_TDFI_RDLVL_RR — Defines the DFI tRDLVL_RR timing parameter [in DFI clocks], the minimum cycles between read commands. Reset Source: ctl_amod_g_rst_n
0x20C8 emif_ctlcfg_DENALI_PI_50
  [31:0] PI_TDFI_RDLVL_RESP — Defines the DFI tRDLVL_RESP timing parameter [in DFI clocks], the maximum cycles between a dfi_rdlvl_req or dfi_rdlvl_gate_req assertion and a dfi_rdlvl_en or dfi_rdlvl_gate_en assertion. Reset Source: ctl_amod_g_rst_n
0x20CC emif_ctlcfg_DENALI_PI_51
  [15:8] PI_TDFI_RDLVL_EN — Defines the DFI tRDLVL_EN timing parameter [in DFI clocks], the minimum cycles from a dfi_rdlvl_en or dfi_rdlvl_gate_en assertion to the first read or MRR. Set to 1 means the minium value[1 cycle], set to 0 means the maxium value Reset Source: ctl_amod_g_rst_n
  [3:0] PI_RDLVL_RESP_MASK — Mask for the dfi_rdlvl_resp signal during data eye training. Reset Source: ctl_amod_g_rst_n
0x20D0 emif_ctlcfg_DENALI_PI_52
  [31:0] PI_TDFI_RDLVL_MAX — Defines the DFI tRDLVL_MAX timing parameter [in DFI clocks], the maximum cycles between a dfi_rdlvl_en or dfi_rdlvl_gate_en assertion and a valid dfi_rdlvl_resp. Reset Source: ctl_amod_g_rst_n
0x20D4 emif_ctlcfg_DENALI_PI_53 access per field
  [23:8] PI_RDLVL_INTERVAL rw — Number of long count sequences counted between automatic data eye training commands. Reset Source: ctl_amod_g_rst_n
  [0] PI_RDLVL_ERROR_STATUS ro — Holds the error associated with the data eye training error or gate training error interrupt. Uppermost bit set indicates a TDFI_RDLVL_RESP parameter violation. Next uppermost bit set indicates a TDFI_RDLVL_MAX parameter violation. Lower bits are reserved. READ-ONLY Reset Source: ctl_amod_g_rst_n
0x20D8 emif_ctlcfg_DENALI_PI_54
  [27:24] PI_RDLVL_PATTERN_NUM — Defines the number of pattern supported in read leveling. Reset Source: ctl_amod_g_rst_n
  [19:16] PI_RDLVL_PATTERN_START — Defines the start pattern in read leveling. Reset Source: ctl_amod_g_rst_n
  [15:0] PI_RDLVL_GATE_INTERVAL — Number of long count sequences counted between automatic gate training commands. Reset Source: ctl_amod_g_rst_n
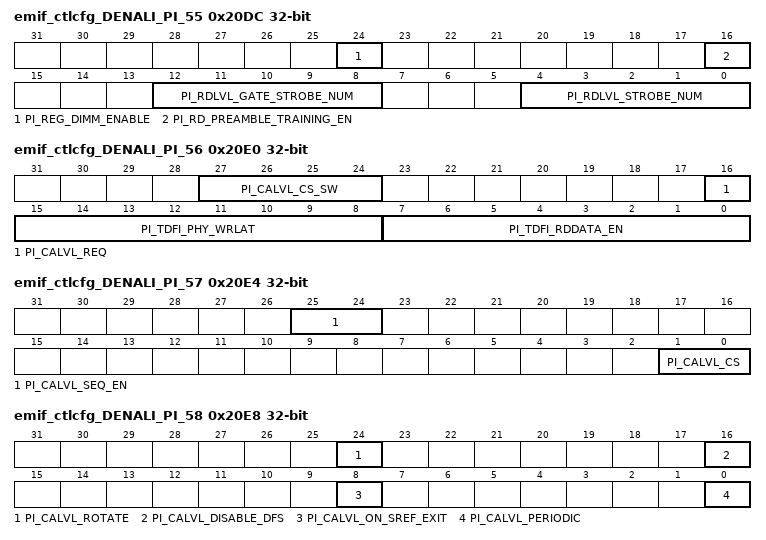
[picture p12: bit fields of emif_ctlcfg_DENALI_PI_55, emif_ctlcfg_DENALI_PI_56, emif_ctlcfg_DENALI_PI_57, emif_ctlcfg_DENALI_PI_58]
0x20DC emif_ctlcfg_DENALI_PI_55
  [24] PI_REG_DIMM_ENABLE — Enable registered DIMM operation. Set to 1 to enable. Reset Source: ctl_amod_g_rst_n
  [16] PI_RD_PREAMBLE_TRAINING_EN — Enable read preamble training during gate training. Set to 1 to enable. Reset Source: ctl_amod_g_rst_n
  [12:8] PI_RDLVL_GATE_STROBE_NUM — Defines the number of back to back MPC command in one read process in read gate training. Reset Source: ctl_amod_g_rst_n
  [4:0] PI_RDLVL_STROBE_NUM — Defines the number of back to back MPC command in one read process in read eye training. Reset Source: ctl_amod_g_rst_n
0x20E0 emif_ctlcfg_DENALI_PI_56 access per field
  [27:24] PI_CALVL_CS_SW rw — Specifies the target chip select for the CA training operation initiated through the CALVL_REQ parameter. Reset Source: ctl_amod_g_rst_n
  [16] PI_CALVL_REQ wo — User request to initiate CA training. Set to 1 to trigger. WRITE-ONLY Reset Source: ctl_amod_g_rst_n
  [15:8] PI_TDFI_PHY_WRLAT ro — Holds the calculated DFI tPHY_WRLAT timing parameter [in DFI PHY clocks], the maximum cycles between a write command and a dfi_wrdata_en assertion. READ-ONLY Reset Source: ctl_amod_g_rst_n
  [7:0] PI_TDFI_RDDATA_EN ro — Holds the calculated DFI tRDDATA_EN timing parameter [in DFI PHY clocks], the maximum cycles between a read command and a dfi_rddata_en assertion. READ-ONLY Reset Source: ctl_amod_g_rst_n
0x20E4 emif_ctlcfg_DENALI_PI_57
  [25:24] PI_CALVL_SEQ_EN — Specifies which CA training patterns will be used. Set to 0 for pattern 0 only, set to 1 for patterns 0 and 1, set to 2 for patterns 0, 1 and 2, or set to 3 for all patterns. Reset Source: ctl_amod_g_rst_n
  [1:0] PI_CALVL_CS — Specifies the target chip select for the CA training operation initiated through the CALVL_REQ parameter. Reset Source: ctl_amod_g_rst_n
0x20E8 emif_ctlcfg_DENALI_PI_58
  [24] PI_CALVL_ROTATE — Enables rotational CS for interval CA training. Set to 1 for rotating CS. Reset Source: ctl_amod_g_rst_n
  [16] PI_CALVL_DISABLE_DFS — Disables automatic CA training on freq change. Set to 1 to disable CA training on dfs, Set to 0 to enable CA training . Reset Source: ctl_amod_g_rst_n
  [8] PI_CALVL_ON_SREF_EXIT — Enables automatic CA training on a self-refresh exit. Set to 1 to enable. Reset Source: ctl_amod_g_rst_n
  [0] PI_CALVL_PERIODIC — Enables the use of the dfi_lvl_periodic signal during CA training. Set to 1 to enable. Reset Source: ctl_amod_g_rst_n
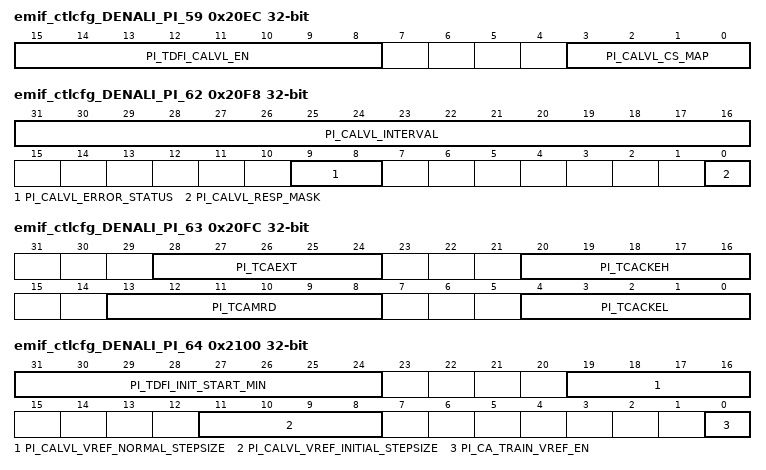
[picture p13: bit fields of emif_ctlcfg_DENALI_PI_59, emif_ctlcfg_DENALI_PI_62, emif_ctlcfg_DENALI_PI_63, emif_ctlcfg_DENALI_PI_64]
0x20EC emif_ctlcfg_DENALI_PI_59
  [15:8] PI_TDFI_CALVL_EN — Defines the DFI tCALVL_EN timing parameter [in DFI clocks], the minimum cycles between a dfi_calvl_en assertion and a dfi_cke de-assertion. Reset Source: ctl_amod_g_rst_n
  [3:0] PI_CALVL_CS_MAP — Defines the chip select map for CA training operations. Bit [0] controls cs0, bit [1] controls cs1, etc. Set each bit to 1 to enable chip for CA training. Reset Source: ctl_amod_g_rst_n
0x20F0 emif_ctlcfg_DENALI_PI_60
  [31:0] PI_TDFI_CALVL_RESP — Defines the DFI tCALVL_RESP timing parameter [in DFI clocks], the maximum cycles between a dfi_calvl_req assertion and a dfi_calvl_en assertion. Reset Source: ctl_amod_g_rst_n
0x20F4 emif_ctlcfg_DENALI_PI_61
  [31:0] PI_TDFI_CALVL_MAX — Defines the DFI tCALVL_MAX timing parameter [in DFI clocks], the maximum cycles between a dfi_calvl_en assertion and a valid dfi_calvl_resp. Reset Source: ctl_amod_g_rst_n
0x20F8 emif_ctlcfg_DENALI_PI_62 access per field
  [31:16] PI_CALVL_INTERVAL rw — Number of long count sequences counted between automatic CA training commands. Reset Source: ctl_amod_g_rst_n
  [9:8] PI_CALVL_ERROR_STATUS ro — Holds the error associated with the CA training error interrupt. Bit [0] set indicates a TDFI_CALVL_RESP parameter violation and bit [1] set indicates a TDFI_CALVL_MAX parameter violation. READ-ONLY Reset Source: ctl_amod_g_rst_n
  [0] PI_CALVL_RESP_MASK rw — Mask for the dfi_calvl_resp signal during CA training. Reset Source: ctl_amod_g_rst_n
0x20FC emif_ctlcfg_DENALI_PI_63
  [28:24] PI_TCAEXT — DRAM tCAEXT value in memory cycles. Reset Source: ctl_amod_g_rst_n
  [20:16] PI_TCACKEH — DRAM tCACKEH value in memory cycles. Reset Source: ctl_amod_g_rst_n
  [13:8] PI_TCAMRD — DRAM tCAMRD value in memory cycles. Reset Source: ctl_amod_g_rst_n
  [4:0] PI_TCACKEL — DRAM tCACKEL value in memory cycles. Reset Source: ctl_amod_g_rst_n
0x2100 emif_ctlcfg_DENALI_PI_64
  [31:24] PI_TDFI_INIT_START_MIN — Minimum number of DFI clocks before dfi_init_start can be driven after a previous command/training event. Reset Source: ctl_amod_g_rst_n
  [19:16] PI_CALVL_VREF_NORMAL_STEPSIZE — The adjust step for the post-initial Vref[ca] training. Reset Source: ctl_amod_g_rst_n
  [11:8] PI_CALVL_VREF_INITIAL_STEPSIZE — The adjust step for the initial Vref[ca] training. Reset Source: ctl_amod_g_rst_n
  [0] PI_CA_TRAIN_VREF_EN — Control for VREF training during CA training post power-on initialization. Set to enable VREF training. Reset Source: ctl_amod_g_rst_n
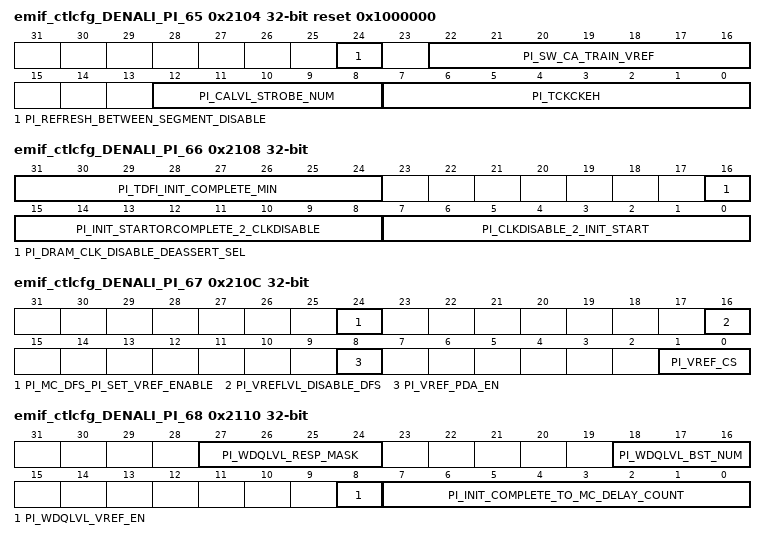
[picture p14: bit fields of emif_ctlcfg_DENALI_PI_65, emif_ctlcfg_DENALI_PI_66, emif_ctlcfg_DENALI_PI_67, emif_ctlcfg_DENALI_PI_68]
0x2104 emif_ctlcfg_DENALI_PI_65 reset 0x1000000
  [24] PI_REFRESH_BETWEEN_SEGMENT_DISABLE — Disable the refresh between CA first and second segment training. Set to 1 to disable. Reset Source: ctl_amod_g_rst_n
  [22:16] PI_SW_CA_TRAIN_VREF — The Vref value which is set for SW step by step CA training. Reset Source: ctl_amod_g_rst_n
  [12:8] PI_CALVL_STROBE_NUM — The consecutive dfi_calvl_strobe number when updating the CA vref data. Reset Source: ctl_amod_g_rst_n
  [7:0] PI_TCKCKEH — DRAM tCKELCK Clock and command valid before CKE HIGH. Reset Source: ctl_amod_g_rst_n
0x2108 emif_ctlcfg_DENALI_PI_66
  [31:24] PI_TDFI_INIT_COMPLETE_MIN — Minimum number of DFI clocks from dfi_init_complete to a command/training event. Reset Source: ctl_amod_g_rst_n
  [16] PI_DRAM_CLK_DISABLE_DEASSERT_SEL — Indicate dfi_dram_clk_disable deassert following dfi_init_start deassert or dfi_init_complete assert. Set to 0: dfi_dram_clk_disable deassert following dfi_init_start deassert. Set to 1: dfi_dram_clk_disable deassert following dfi_init_complete assert. Reset Source: ctl_amod_g_rst_n
  [15:8] PI_INIT_STARTORCOMPLETE_2_CLKDISABLE — Defines the delay from deasserting of dfi_init_start or asserting of dfi_init_complete to deasserting of dfi_dram_clk_disable in DFI clock. Reset Source: ctl_amod_g_rst_n
  [7:0] PI_CLKDISABLE_2_INIT_START — Defines the delay from the asserting of dfi_dram_clk_disable to the asserting of dfi_init_start in DFI clock. Reset Source: ctl_amod_g_rst_n
0x210C emif_ctlcfg_DENALI_PI_67
  [24] PI_MC_DFS_PI_SET_VREF_ENABLE — Enable the PI to set VREF value after DFS issued by MC. MR12 and MR14 for LPDDR4. MR6 for DDR4. 1 means disable. Reset Source: ctl_amod_g_rst_n
  [16] PI_VREFLVL_DISABLE_DFS — Disables automatic VREF training on freq change. Set to 1 to disable. Reset Source: ctl_amod_g_rst_n
  [8] PI_VREF_PDA_EN — Enable per-DRAM addressability during VREF training. Set to 1 to enable. Reset Source: ctl_amod_g_rst_n
  [1:0] PI_VREF_CS — Specifies the target chip select for the VREF training operation. Reset Source: ctl_amod_g_rst_n
0x2110 emif_ctlcfg_DENALI_PI_68
  [27:24] PI_WDQLVL_RESP_MASK — Write DQ training response mask. When set to 1, the dfi_wdqlvl_en of the slice is not asserted. Reset Source: ctl_amod_g_rst_n
  [18:16] PI_WDQLVL_BST_NUM — Defines the number of write/read bursts issued at each step in write DQ training. Reset Source: ctl_amod_g_rst_n
  [8] PI_WDQLVL_VREF_EN — Control for VREF training as part of non-initialization write DQ training. Reset Source: ctl_amod_g_rst_n
  [7:0] PI_INIT_COMPLETE_TO_MC_DELAY_COUNT — It controls the time PI bypass CKE at the beginning of PI mask dfi_init_complete to controller. Reset Source: ctl_amod_g_rst_n
0x2114 emif_ctlcfg_DENALI_PI_69
  [28:24] PI_WDQLVL_VREF_NORMAL_STEPSIZE — Write DQ training vref step size for post_initial training. Reset Source: ctl_amod_g_rst_n
  [20:16] PI_WDQLVL_VREF_INITIAL_STEPSIZE — Write DQ training vref step size for initial training. Reset Source: ctl_amod_g_rst_n
  [11:8] PI_WDQLVL_CS_MAP — Map of CS's included in write DQ training sequence. Reset Source: ctl_amod_g_rst_n
  [0] PI_WDQLVL_ROTATE — Enables write DQ training rotate for interval training. Reset Source: ctl_amod_g_rst_n
0x2118 emif_ctlcfg_DENALI_PI_70 access per field
  [25:24] PI_WDQLVL_CS rw — Write DQ training target chip select. Reset Source: ctl_amod_g_rst_n
  [19:16] PI_WDQLVL_CS_SW rw — Write DQ training target chip select. Reset Source: ctl_amod_g_rst_n
  [8] PI_WDQLVL_REQ wo — SW write to initiate Write DQ training request. WRITE-ONLY Reset Source: ctl_amod_g_rst_n
  [0] PI_WDQLVL_PERIODIC rw — Enables periodic write DQ training. Reset Source: ctl_amod_g_rst_n
0x211C emif_ctlcfg_DENALI_PI_71
  [7:0] PI_TDFI_WDQLVL_EN — DFI timing param tWDQLVL_EN. Minimum number of DFI clocks required after the write DQ training enable signal is asserted until the first write command may be asserted. Reset Source: ctl_amod_g_rst_n
0x2120 emif_ctlcfg_DENALI_PI_72
  [31:0] PI_TDFI_WDQLVL_RESP — DFI timing param tWDQLVL_RESP. Maximum number of DFI clocks that may occur between a write DQ training request and the associated mode enable. Reset Source: ctl_amod_g_rst_n
0x2124 emif_ctlcfg_DENALI_PI_73
  [31:0] PI_TDFI_WDQLVL_MAX — DFI timing param tWDQLVL_MAX. Maximum number of DFI clocks that the PI will wait for a response from the PHY. Reset Source: ctl_amod_g_rst_n
